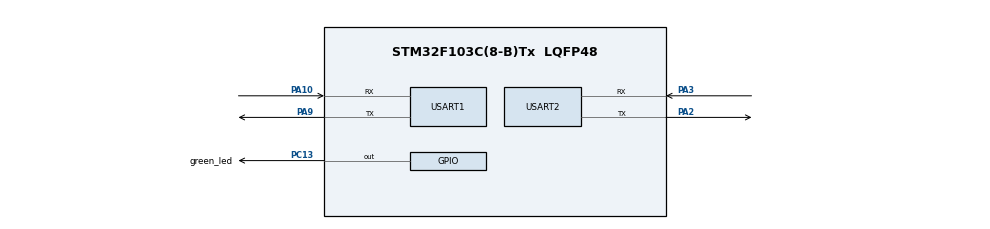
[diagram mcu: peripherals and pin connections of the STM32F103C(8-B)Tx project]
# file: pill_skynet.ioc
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Mcu.Family=STM32F1
Mcu.Name=STM32F103C(8-B)Tx
Mcu.Package=LQFP48
NVIC.PriorityGroup=NVIC_PRIORITYGROUP_4
PA10.Mode=Asynchronous
PA10.Signal=USART1_RX
PA2.Mode=Asynchronous
PA2.Signal=USART2_TX
PA3.Mode=Asynchronous
PA3.Signal=USART2_RX
PA9.Mode=Asynchronous
PA9.Signal=USART1_TX
PC13-TAMPER-RTC.GPIO_Label=green_led
PC13-TAMPER-RTC.Signal=GPIO_Output
ProjectManager.HeapSize=0x200
ProjectManager.StackSize=0x400
ProjectManager.TargetToolchain=MDK-ARM V5.27
RCC.APB1Freq_Value=8000000
RCC.APB2Freq_Value=8000000
USART1.VirtualMode=VM_ASYNC
USART2.VirtualMode=VM_ASYNC
VP_SYS_VS_ND.Mode=No_Debug
board=custom

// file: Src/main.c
/* USER CODE BEGIN Header */
/**
  ******************************************************************************
  * @file           : main.c
  * @brief          : Main program body
  ******************************************************************************
  * @attention
  *
  * <h2><center>&copy; Copyright (c) 2020 STMicroelectronics.
  * All rights reserved.</center></h2>
  *
  * This software component is licensed by ST under BSD 3-Clause license,
  * the "License"; You may not use this file except in compliance with the
  * License. You may obtain a copy of the License at:
  *                        opensource.org/licenses/BSD-3-Clause
  *
  ******************************************************************************
  */
/* USER CODE END Header */

#include "main.h"
#include "string.h"

UART_HandleTypeDef huart1;
UART_HandleTypeDef huart2;

//UART methods
void transmit_bt_char(char c);
void transmit_bt(char* chars);
void transmit_lora_char(char c);
void transmit_lora(char* chars);

void SystemClock_Config(void);
static void MX_GPIO_Init(void);
static void MX_USART1_UART_Init(void);
static void MX_USART2_UART_Init(void);

void debugPrintln(UART_HandleTypeDef *huart, char _out[]){
 HAL_UART_Transmit(huart, (uint8_t *) _out, strlen(_out), 10);
 char newline[2] = "\r\n";
 HAL_UART_Transmit(huart, (uint8_t *) newline, 2, 10);
}

int main(void)
{

  /* MCU Configuration--------------------------------------------------------*/

  /* Reset of all peripherals, Initializes the Flash interface and the Systick. */
  HAL_Init();

  /* Configure the system clock */
  SystemClock_Config();

  /* Initialize all configured peripherals */
  MX_GPIO_Init();
  MX_USART1_UART_Init();
  MX_USART2_UART_Init();

// debugPrintln(&huart2, "Starting"); // print full line
 transmit_bt("Starting\r\n");
 transmit_lora("STM32f1 has started\r\n");

  /* Infinite loop */
  while (1)
  {
    /* USER CODE BEGIN 3 */
		HAL_GPIO_TogglePin(green_led_GPIO_Port, green_led_Pin);
		HAL_Delay(1000);
  }
  /* USER CODE END 3 */
}

//The LoRa module is using uart2, so when LoRa data comes in,
//relay it to the bluetooth app
void USART2_IRQHandler(void)
{
	char characters[256];
	uint32_t character_iter = 0;
	while((USART2->SR >> 5) & 1)
	{
		characters[character_iter] = USART2->DR;
		character_iter++;
	}
	characters[character_iter] = 0;
	transmit_bt(characters);
}

//The bluetooth module is using uart1, so when data comes in,
//relay it to the LoRa module
void USART1_IRQHandler(void)
{
	char characters[256];
	uint32_t character_iter = 0;
	while((USART1->SR >> 5) & 1)
	{
		characters[character_iter] = USART1->DR;
		character_iter++;
		if((USART1->SR >> 3) & 1)
			transmit_bt("overrun occured");
	}
	characters[character_iter] = 0;
	transmit_lora(characters);
}

void transmit_lora_char(char c)
{
	while(!(USART2->SR & (1 << 7))) //check for the transmission to be clear for the next byte
	{
	}
	USART2->DR = c; //set the character to be transmitted
}

void transmit_lora(char* chars)
{
	//loop through all the characters checking for null and an invalid pointer
	uint32_t counter = 0;
	while(chars != 0 && chars[counter] != 0)
	{
		transmit_lora_char(chars[counter]);
		counter++;
	}
}

void transmit_bt_char(char c)
{
	while(!(USART1->SR & (1 << 7))) //check for the transmission to be clear for the next byte
	{
	}
	USART1->DR = c; //set the character to be transmitted
}

void transmit_bt(char* chars)
{
	//loop through all the characters checking for null and an invalid pointer
	uint32_t counter = 0;
	while(chars != 0 && chars[counter] != 0)
	{
		transmit_bt_char(chars[counter]);
		counter++;
	}
}

void SystemClock_Config(void)
{
  RCC_OscInitTypeDef RCC_OscInitStruct = {0};
  RCC_ClkInitTypeDef RCC_ClkInitStruct = {0};

  /** Initializes the CPU, AHB and APB busses clocks
  */
  RCC_OscInitStruct.OscillatorType = RCC_OSCILLATORTYPE_HSI;
  RCC_OscInitStruct.HSIState = RCC_HSI_ON;
  RCC_OscInitStruct.HSICalibrationValue = RCC_HSICALIBRATION_DEFAULT;
  RCC_OscInitStruct.PLL.PLLState = RCC_PLL_NONE;
  if (HAL_RCC_OscConfig(&RCC_OscInitStruct) != HAL_OK)
  {
    Error_Handler();
  }
  /** Initializes the CPU, AHB and APB busses clocks
  */
  RCC_ClkInitStruct.ClockType = RCC_CLOCKTYPE_HCLK|RCC_CLOCKTYPE_SYSCLK
                              |RCC_CLOCKTYPE_PCLK1|RCC_CLOCKTYPE_PCLK2;
  RCC_ClkInitStruct.SYSCLKSource = RCC_SYSCLKSOURCE_HSI;
  RCC_ClkInitStruct.AHBCLKDivider = RCC_SYSCLK_DIV1;
  RCC_ClkInitStruct.APB1CLKDivider = RCC_HCLK_DIV1;
  RCC_ClkInitStruct.APB2CLKDivider = RCC_HCLK_DIV1;

  if (HAL_RCC_ClockConfig(&RCC_ClkInitStruct, FLASH_LATENCY_0) != HAL_OK)
  {
    Error_Handler();
  }
}

static void MX_USART1_UART_Init(void)
{

  huart1.Instance = USART1;
  huart1.Init.BaudRate = 115200;
  huart1.Init.WordLength = UART_WORDLENGTH_8B;
  huart1.Init.StopBits = UART_STOPBITS_1;
  huart1.Init.Parity = UART_PARITY_NONE;
  huart1.Init.Mode = UART_MODE_TX_RX;
  huart1.Init.HwFlowCtl = UART_HWCONTROL_NONE;
  huart1.Init.OverSampling = UART_OVERSAMPLING_16;
  if (HAL_UART_Init(&huart1) != HAL_OK)
  {
    Error_Handler();
  }
  /* USER CODE BEGIN USART1_Init 2 */

	USART1->CR1 |= (1<<5);

  /* USER CODE END USART1_Init 2 */
	NVIC_EnableIRQ(USART1_IRQn);
	NVIC_SetPriority(USART1_IRQn, 1);

}

static void MX_USART2_UART_Init(void)
{

  huart2.Instance = USART2;
  huart2.Init.BaudRate = 115200;
  huart2.Init.WordLength = UART_WORDLENGTH_8B;
  huart2.Init.StopBits = UART_STOPBITS_1;
  huart2.Init.Parity = UART_PARITY_NONE;
  huart2.Init.Mode = UART_MODE_TX_RX;
  huart2.Init.HwFlowCtl = UART_HWCONTROL_NONE;
  huart2.Init.OverSampling = UART_OVERSAMPLING_16;
  if (HAL_UART_Init(&huart2) != HAL_OK)
  {
    Error_Handler();
  }
  /* USER CODE BEGIN USART2_Init 2 */

	USART2->CR1 |= (1<<5);

  /* USER CODE END USART2_Init 2 */

	NVIC_EnableIRQ(USART2_IRQn);
	NVIC_SetPriority(USART2_IRQn, 1);

}

static void MX_GPIO_Init(void)
{
  GPIO_InitTypeDef GPIO_InitStruct = {0};

  /* GPIO Ports Clock Enable */
  __HAL_RCC_GPIOC_CLK_ENABLE();
  __HAL_RCC_GPIOA_CLK_ENABLE();

  /*Configure GPIO pin Output Level */
  HAL_GPIO_WritePin(green_led_GPIO_Port, green_led_Pin, GPIO_PIN_RESET);

  /*Configure GPIO pin : green_led_Pin */
  GPIO_InitStruct.Pin = green_led_Pin;
  GPIO_InitStruct.Mode = GPIO_MODE_OUTPUT_PP;
  GPIO_InitStruct.Pull = GPIO_NOPULL;
  GPIO_InitStruct.Speed = GPIO_SPEED_FREQ_LOW;
  HAL_GPIO_Init(green_led_GPIO_Port, &GPIO_InitStruct);

}

void Error_Handler(void)
{
}

/************************ (C) COPYRIGHT STMicroelectronics *****END OF FILE****/
